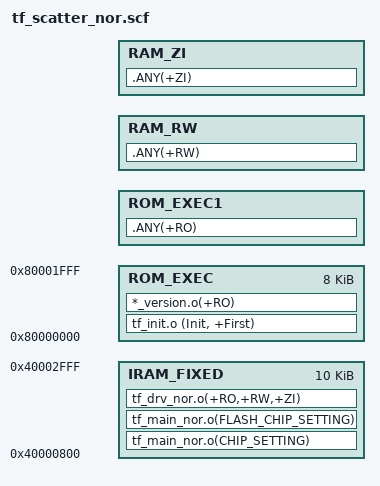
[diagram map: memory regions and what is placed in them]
ROM_LOAD 0x80000000 0x100000
{
    ROM_EXEC 0x80000000 0x2000
    {
        tf_init.o (Init, +First)
       	*_version.o(+RO)
    }
    ROM_EXEC1 +0x0
    {
    	.ANY(+RO)
    }
    RAM_RW +0x0
    {   
    	.ANY(+RW)
    } 
    RAM_ZI +0x0
    {   
    	.ANY(+ZI)
    }

    IRAM_FIXED 0x40000800 0x2800
    {
     	 tf_main_nor.o(CHIP_SETTING)
     	 tf_main_nor.o(FLASH_CHIP_SETTING)
     	 tf_drv_nor.o(+RO,+RW,+ZI)
    }
}
